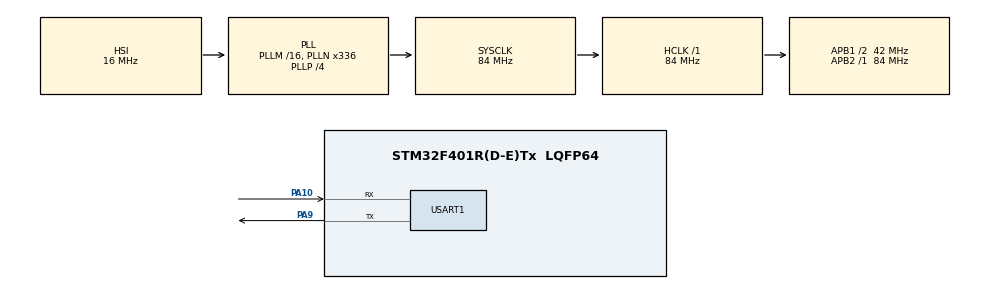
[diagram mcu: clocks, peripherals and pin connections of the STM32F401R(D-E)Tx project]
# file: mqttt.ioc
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Mcu.Family=STM32F4
Mcu.Name=STM32F401R(D-E)Tx
Mcu.Package=LQFP64
NVIC.PriorityGroup=NVIC_PRIORITYGROUP_4
NVIC.USART1_IRQn=true\:0\:0\:false\:false\:true\:true\:true\:true
PA10.Mode=Asynchronous
PA10.Signal=USART1_RX
PA13.Mode=Serial_Wire
PA13.Signal=SYS_JTMS-SWDIO
PA14.Mode=Serial_Wire
PA14.Signal=SYS_JTCK-SWCLK
PA9.Mode=Asynchronous
PA9.Signal=USART1_TX
PH0\ -\ OSC_IN.Mode=HSE-External-Clock-Source
PH0\ -\ OSC_IN.Signal=RCC_OSC_IN
PH1\ -\ OSC_OUT.Mode=HSE-External-Clock-Source
PH1\ -\ OSC_OUT.Signal=RCC_OSC_OUT
ProjectManager.HeapSize=0x200
ProjectManager.StackSize=0x400
ProjectManager.TargetToolchain=MDK-ARM V5.32
RCC.48MHZClocksFreq_Value=42000000
RCC.AHBFreq_Value=84000000
RCC.APB1CLKDivider=RCC_HCLK_DIV2
RCC.APB1Freq_Value=42000000
RCC.APB1TimFreq_Value=84000000
RCC.APB2Freq_Value=84000000
RCC.APB2TimFreq_Value=84000000
RCC.CortexFreq_Value=84000000
RCC.HCLKFreq_Value=84000000
RCC.HSE_VALUE=25000000
RCC.HSI_VALUE=16000000
RCC.LSE_VALUE=32768
RCC.PLLM=25
RCC.PLLN=168
RCC.PLLSourceVirtual=RCC_PLLSOURCE_HSE
RCC.SYSCLKFreq_VALUE=84000000
RCC.SYSCLKSource=RCC_SYSCLKSOURCE_PLLCLK
RCC.VCOOutputFreq_Value=168000000
USART1.VirtualMode=VM_ASYNC
board=custom

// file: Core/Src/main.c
/* USER CODE BEGIN Header */
/**
  ******************************************************************************
  * @file           : main.c
  * @brief          : Main program body
  ******************************************************************************
  * @attention
  *
  * Copyright (c) 2026 STMicroelectronics.
  * All rights reserved.
  *
  * This software is licensed under terms that can be found in the LICENSE file
  * in the root directory of this software component.
  * If no LICENSE file comes with this software, it is provided AS-IS.
  *
  ******************************************************************************
  */
/* USER CODE END Header */
#include "main.h"
#include "ESPLib.h"

UART_HandleTypeDef huart1;

void SystemClock_Config(void);
static void MX_GPIO_Init(void);
static void MX_USART1_UART_Init(void);

int main(void)
{

  /* MCU Configuration--------------------------------------------------------*/

  /* Reset of all peripherals, Initializes the Flash interface and the Systick. */
  HAL_Init();

	uint32_t previousTime = HAL_GetTick();

  /* Configure the system clock */
  SystemClock_Config();

  /* Initialize all configured peripherals */
  MX_GPIO_Init();
  MX_USART1_UART_Init();

 	 ESP8266_Init(StationMode, huart1);

  // 2. Connect to your local Wi-Fi network (Replace with your Router SSID and Password)
 ESP8266_wifiConnect("SNUC", "snu12345");

 // 3. Connect to your MQTT Broker (Replace with your Broker's IP Address)
 // 1883 is the standard unencrypted MQTT port
 ESP8266_portConnect("TCP", "broker.emqx.io", "1883");

 // 4. Configure the MQTT client connection parameters
 MQTT_InitTypeDef_t mqttSetting;
 mqttSetting.keepAlive = 500;

 mqttSetting.clientID = "BluePill_MQTT_01";
mqttSetting.username = NULL;
mqttSetting.password = NULL;

mqttSetting.connectFlag = CleanSession;
MQTT_connectBroker(&mqttSetting);

  /* Infinite loop */
  /* USER CODE BEGIN WHILE */
  while (1)
  {if (HAL_GetTick() - previousTime >= 1000)
    {
        previousTime = HAL_GetTick();

        MQTT_publishTopic("stm32/test/data", "diya", QoS0);
    }
    /* USER CODE END WHILE */

  }
}

void SystemClock_Config(void)
{
    RCC_OscInitTypeDef RCC_OscInitStruct = {0};
    RCC_ClkInitTypeDef RCC_ClkInitStruct = {0};

    /* Enable Power Control clock */
    __HAL_RCC_PWR_CLK_ENABLE();

    /* Configure voltage scaling */
    __HAL_PWR_VOLTAGESCALING_CONFIG(PWR_REGULATOR_VOLTAGE_SCALE2);

    /* Configure HSI and PLL */
    RCC_OscInitStruct.OscillatorType = RCC_OSCILLATORTYPE_HSI;
    RCC_OscInitStruct.HSIState = RCC_HSI_ON;
    RCC_OscInitStruct.HSICalibrationValue = RCC_HSICALIBRATION_DEFAULT;

    RCC_OscInitStruct.PLL.PLLState = RCC_PLL_ON;
    RCC_OscInitStruct.PLL.PLLSource = RCC_PLLSOURCE_HSI;

    RCC_OscInitStruct.PLL.PLLM = 16;
    RCC_OscInitStruct.PLL.PLLN = 336;
    RCC_OscInitStruct.PLL.PLLP = RCC_PLLP_DIV4;
    RCC_OscInitStruct.PLL.PLLQ = 7;

    if (HAL_RCC_OscConfig(&RCC_OscInitStruct) != HAL_OK)
    {
        Error_Handler();
    }

    /* Configure CPU, AHB and APB clocks */
    RCC_ClkInitStruct.ClockType = RCC_CLOCKTYPE_HCLK |
                                  RCC_CLOCKTYPE_SYSCLK |
                                  RCC_CLOCKTYPE_PCLK1 |
                                  RCC_CLOCKTYPE_PCLK2;

    RCC_ClkInitStruct.SYSCLKSource = RCC_SYSCLKSOURCE_PLLCLK;
    RCC_ClkInitStruct.AHBCLKDivider = RCC_SYSCLK_DIV1;
    RCC_ClkInitStruct.APB1CLKDivider = RCC_HCLK_DIV2;
    RCC_ClkInitStruct.APB2CLKDivider = RCC_HCLK_DIV1;

    if (HAL_RCC_ClockConfig(&RCC_ClkInitStruct, FLASH_LATENCY_2) != HAL_OK)
    {
        Error_Handler();
    }
}

static void MX_GPIO_Init(void)
{

  /* GPIO Ports Clock Enable */
  __HAL_RCC_GPIOH_CLK_ENABLE();
  __HAL_RCC_GPIOA_CLK_ENABLE();

}

static void MX_USART1_UART_Init(void)
{
    huart1.Instance = USART1;
    huart1.Init.BaudRate = 115200;
    huart1.Init.WordLength = UART_WORDLENGTH_8B;
    huart1.Init.StopBits = UART_STOPBITS_1;
    huart1.Init.Parity = UART_PARITY_NONE;
    huart1.Init.Mode = UART_MODE_TX_RX;
    huart1.Init.HwFlowCtl = UART_HWCONTROL_NONE;
    huart1.Init.OverSampling = UART_OVERSAMPLING_16;

    if (HAL_UART_Init(&huart1) != HAL_OK)
    {
        Error_Handler();
    }
}

void Error_Handler(void)
{
  __disable_irq();
  while (1)
  {
  }
}
